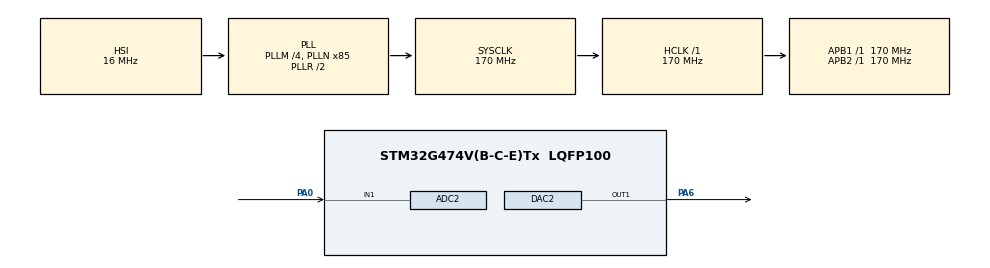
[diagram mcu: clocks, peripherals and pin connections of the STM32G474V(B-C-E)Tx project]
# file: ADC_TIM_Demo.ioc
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ADC2.Channel-0\#ChannelRegularConversion=ADC_CHANNEL_1
ADC2.ExternalTrigConv=ADC_EXTERNALTRIG_T6_TRGO
ADC2.NbrOfConversionFlag=1
ADC2.OffsetNumber-0\#ChannelRegularConversion=ADC_OFFSET_NONE
ADC2.Rank-0\#ChannelRegularConversion=1
ADC2.SamplingTime-0\#ChannelRegularConversion=ADC_SAMPLETIME_2CYCLES_5
Mcu.Family=STM32G4
Mcu.Name=STM32G474V(B-C-E)Tx
Mcu.Package=LQFP100
NVIC.PriorityGroup=NVIC_PRIORITYGROUP_4
PA0.Mode=IN1-Single-Ended
PA0.Signal=ADC2_IN1
PA13.Mode=Serial_Wire
PA13.Signal=SYS_JTMS-SWDIO
PA14.Mode=Serial_Wire
PA14.Signal=SYS_JTCK-SWCLK
PA6.Signal=COMP_DAC21_group
PC14-OSC32_IN.Mode=LSE-External-Oscillator
PC14-OSC32_IN.Signal=RCC_OSC32_IN
PC15-OSC32_OUT.Mode=LSE-External-Oscillator
PC15-OSC32_OUT.Signal=RCC_OSC32_OUT
PF0-OSC_IN.Mode=HSE-External-Oscillator
PF0-OSC_IN.Signal=RCC_OSC_IN
PF1-OSC_OUT.Mode=HSE-External-Oscillator
PF1-OSC_OUT.Signal=RCC_OSC_OUT
ProjectManager.HeapSize=0x200
ProjectManager.StackSize=0x400
ProjectManager.TargetToolchain=MDK-ARM V5.32
RCC.ADC12Freq_Value=170000000
RCC.ADC345Freq_Value=170000000
RCC.AHBFreq_Value=170000000
RCC.APB1Freq_Value=170000000
RCC.APB1TimFreq_Value=170000000
RCC.APB2Freq_Value=170000000
RCC.APB2TimFreq_Value=170000000
RCC.CortexFreq_Value=170000000
RCC.EXTERNAL_CLOCK_VALUE=12288000
RCC.HCLKFreq_Value=170000000
RCC.HSE_VALUE=8000000
RCC.HSI48_VALUE=48000000
RCC.HSI_VALUE=16000000
RCC.PLLM=RCC_PLLM_DIV4
RCC.PLLN=85
RCC.SYSCLKFreq_VALUE=170000000
RCC.SYSCLKSource=RCC_SYSCLKSOURCE_PLLCLK
RCC.USBFreq_Value=170000000
RCC.VCOOutputFreq_Value=340000000
SH.COMP_DAC21_group.0=DAC2_OUT1,DAC_OUT1
TIM6.AutoReloadPreload=TIM_AUTORELOAD_PRELOAD_ENABLE
TIM6.PeriodNoDither=8500-1
TIM6.TIM_MasterOutputTrigger=TIM_TRGO_UPDATE
VP_SYS_VS_DBSignals.Mode=DisableDeadBatterySignals
VP_TIM6_VS_ClockSourceINT.Mode=Enable_Timer
board=custom

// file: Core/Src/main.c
/* USER CODE BEGIN Header */
/**
  ******************************************************************************
  * @file           : main.c
  * @brief          : Main program body
  ******************************************************************************
  * @attention
  *
  * Copyright (c) 2025 STMicroelectronics.
  * All rights reserved.
  *
  * This software is licensed under terms that can be found in the LICENSE file
  * in the root directory of this software component.
  * If no LICENSE file comes with this software, it is provided AS-IS.
  *
  ******************************************************************************
  */
/* USER CODE END Header */
#include "main.h"
#include "adc.h"
#include "dac.h"
#include "tim.h"
#include "gpio.h"

void SystemClock_Config(void);

/* USER CODE BEGIN 0 */
uint16_t ADC_Value;
/* USER CODE END 0 */

int main(void)
{

  /* MCU Configuration--------------------------------------------------------*/

  /* Reset of all peripherals, Initializes the Flash interface and the Systick. */
  HAL_Init();

  /* Configure the system clock */
  SystemClock_Config();

  /* Initialize all configured peripherals */
  MX_GPIO_Init();
  MX_ADC2_Init();
  MX_DAC2_Init();
  MX_TIM6_Init();
  /* USER CODE BEGIN 2 */

	HAL_ADCEx_Calibration_Start(&hadc2,ADC_SINGLE_ENDED);
  HAL_DAC_SetValue(&hdac2, DAC_CHANNEL_1, DAC_ALIGN_12B_R, 3000);
	HAL_DAC_Start(&hdac2,DAC_CHANNEL_1);
	HAL_TIM_Base_Start(&htim6);
	HAL_ADC_Start(&hadc2);

  /* USER CODE END 2 */

  /* Infinite loop */
  /* USER CODE BEGIN WHILE */
  while (1)
  {
		ADC_Value = HAL_ADC_GetValue(&hadc2);

    /* USER CODE END WHILE */

  }
}

void SystemClock_Config(void)
{
  RCC_OscInitTypeDef RCC_OscInitStruct = {0};
  RCC_ClkInitTypeDef RCC_ClkInitStruct = {0};

  /** Configure the main internal regulator output voltage
  */
  HAL_PWREx_ControlVoltageScaling(PWR_REGULATOR_VOLTAGE_SCALE1_BOOST);

  /** Initializes the RCC Oscillators according to the specified parameters
  * in the RCC_OscInitTypeDef structure.
  */
  RCC_OscInitStruct.OscillatorType = RCC_OSCILLATORTYPE_HSI;
  RCC_OscInitStruct.HSIState = RCC_HSI_ON;
  RCC_OscInitStruct.HSICalibrationValue = RCC_HSICALIBRATION_DEFAULT;
  RCC_OscInitStruct.PLL.PLLState = RCC_PLL_ON;
  RCC_OscInitStruct.PLL.PLLSource = RCC_PLLSOURCE_HSI;
  RCC_OscInitStruct.PLL.PLLM = RCC_PLLM_DIV4;
  RCC_OscInitStruct.PLL.PLLN = 85;
  RCC_OscInitStruct.PLL.PLLP = RCC_PLLP_DIV2;
  RCC_OscInitStruct.PLL.PLLQ = RCC_PLLQ_DIV2;
  RCC_OscInitStruct.PLL.PLLR = RCC_PLLR_DIV2;
  if (HAL_RCC_OscConfig(&RCC_OscInitStruct) != HAL_OK)
  {
    Error_Handler();
  }

  /** Initializes the CPU, AHB and APB buses clocks
  */
  RCC_ClkInitStruct.ClockType = RCC_CLOCKTYPE_HCLK|RCC_CLOCKTYPE_SYSCLK
                              |RCC_CLOCKTYPE_PCLK1|RCC_CLOCKTYPE_PCLK2;
  RCC_ClkInitStruct.SYSCLKSource = RCC_SYSCLKSOURCE_PLLCLK;
  RCC_ClkInitStruct.AHBCLKDivider = RCC_SYSCLK_DIV1;
  RCC_ClkInitStruct.APB1CLKDivider = RCC_HCLK_DIV1;
  RCC_ClkInitStruct.APB2CLKDivider = RCC_HCLK_DIV1;

  if (HAL_RCC_ClockConfig(&RCC_ClkInitStruct, FLASH_LATENCY_4) != HAL_OK)
  {
    Error_Handler();
  }
}

void Error_Handler(void)
{
  __disable_irq();
  while (1)
  {
  }
}
